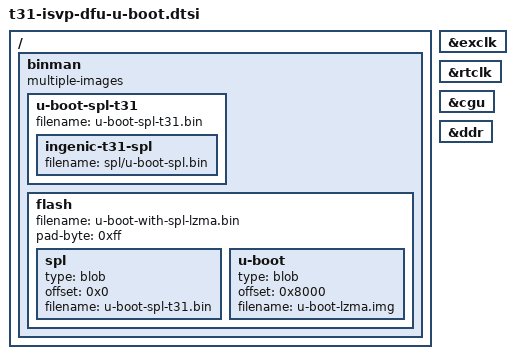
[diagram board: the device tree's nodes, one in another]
// SPDX-License-Identifier: GPL-2.0+
/*
 * Binman image description for the Ingenic ISVP-T31 DFU loader (USB-boot; binman image unused).
 *
 * The USB-boot path uploads spl/u-boot-spl.bin + u-boot-lzma.img
 * directly via the mask ROM (t31-usbboot.py), so the binman flash
 * images here are not used in the USB-boot flow. They are kept
 * consistent with the production t31-isvp layout (LZMA U-Boot at
 * 0x8000, not 0x10000) so a stray `make` of this config still
 * produces a sensible flash image. Outputs:
 *
 *   u-boot-spl-t31.bin : SPL with the finalized SFC-NOR boot header.
 *   u-boot-with-spl-lzma.bin : headered SPL at offset 0 and
 *                              LZMA U-Boot at the SPL-loader
 *                              offset (no 0xff padding).
 */

/ {
	binman: binman {
		multiple-images;
	};
};

&binman {
	u-boot-spl-t31 {
		filename = "u-boot-spl-t31.bin";

		ingenic-t31-spl {
			filename = "spl/u-boot-spl.bin";
		};
	};

	flash {
		filename = "u-boot-with-spl-lzma.bin";
		pad-byte = <0xff>;

		spl {
			type = "blob";
			offset = <0x0>;
			filename = "u-boot-spl-t31.bin";
		};

		u-boot {
			type = "blob";
			offset = <0x8000>;
			filename = "u-boot-lzma.img";
		};
	};
};

/*
 * Keep the DDR controller (and its clock tree) in the SPL devicetree so
 * the UCLASS_RAM probe can bind ingenic,t31-ddr and run sdram_init().
 * Without this the SPL hangs at uclass_first_device_err(UCLASS_RAM)
 * before DDR is up (the node is otherwise stripped from the SPL DT).
 */
&exclk { bootph-all; };
&rtclk { bootph-all; };
&cgu { bootph-all; };
&ddr { bootph-all; };
